# WB32F10x register map
File version: 1.2
CPU: CM3 r2p0, little endian, MPU, no FPU, 4 interrupt priority bits
Registers are 32-bit, read-write, reset 0x0 unless marked. A register's access mark holds for its fields unless they carry their own. Offsets are from the block's base; [hi:lo] are bit positions.

## UART1 — Universal Asynchronous 1
Base 0x40003800
Same registers: UART2 0x40008000, UART3 0x40008400
0x00 RBR ro reset not defined — Receive buffer register
  [8:0] RBR — Receive buffer
0x00 THR wo reset not defined (alternate view of RBR) — Transmit holding register
  [8:0] THR — Transmit hold
0x00 DLL reset not defined (alternate view of RBR) — Divisor latch low register
  [7:0] DLLSB — Divisor latch LSB
0x04 DLH — Divisor latch high register
  [7:0] DLHSB — Divisor latch HSB
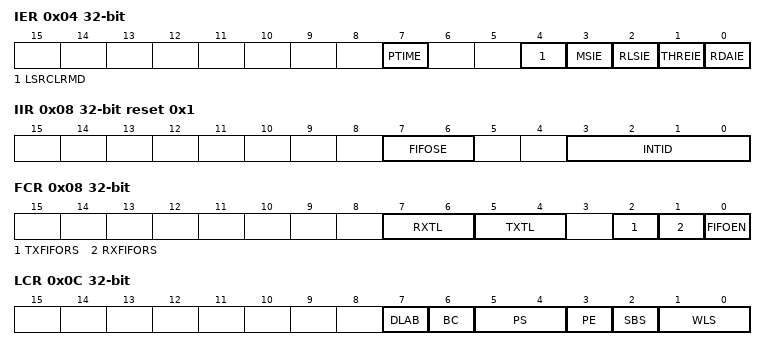
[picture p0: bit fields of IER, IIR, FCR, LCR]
0x04 IER (alternate view of DLH) — Interrupt enable register
  [7] PTIME — Control programmable THRE interrupt.
  [4] LSRCLRMD — This bit is used to control the clearing mode of status bit in LSR register
  [3] MSIE — Modem interrupt control
  [2] RLSIE — Receive interrupt line enable
  [1] THREIE — THRE interrupt enable
  [0] RDAIE — RBR interrupt enable
0x08 IIR ro reset 0x1 — Interrupt identification register
  [7:6] FIFOSE — FIFO enable
  [3:0] INTID — Interrupt identification
0x08 FCR wo (alternate view of IIR) — FIFO control register
  [7:6] RXTL — Receive trigger level
  [5:4] TXTL — Transmit trigger level
  [2] TXFIFORS — Transmit FIFO reset
  [1] RXFIFORS — Receive FIFO reset
  [0] FIFOEN — FIFO enable
0x0C LCR — Line control register
  [7] DLAB — Divisor latch access bit
  [6] BC — Interval control
  [5:4] PS — Parity check selection
  [3] PE — Parity check enable
  [2] SBS — Stop bit selection
  [1:0] WLS — Word length selection
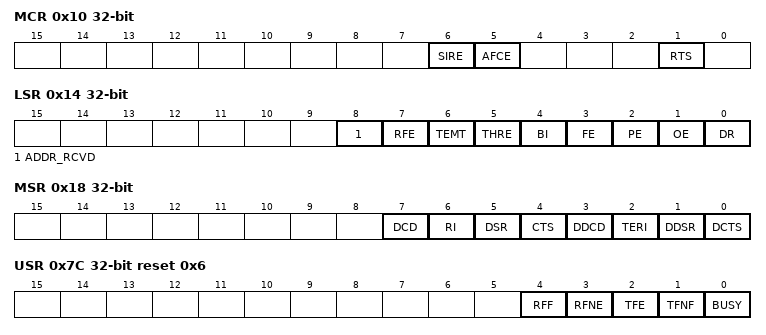
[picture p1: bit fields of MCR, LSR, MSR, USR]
0x10 MCR — Modem control register
  [6] SIRE — IrDA SIR enable
  [5] AFCE — Automatic flow control
  [1] RTS — Modem output pin RTS source
0x14 LSR ro — Line status register
  [8] ADDR_RCVD — Address receive bit
  [7] RFE — Receive FIFO error
  [6] TEMT — Transmitter is empty
  [5] THRE — Transmitter holds the register empty
  [4] BI — Interval interrupt
  [3] FE — Framing error
  [2] PE — Parity check error
  [1] OE — Overflow error
  [0] DR — Data receive ready
0x18 MSR ro — Modem status register
  [7] DCD — Data carrier detection status
  [6] RI — Ringing indicator status
  [5] DSR — Data set ready state
  [4] CTS — Clear transmit status
  [3] DDCD — Delta DCD
  [2] TERI — This bit is set when the input RI is converted from low level to high level
  [1] DDSR — Delta DSR
  [0] DCTS — Delta CTS
0x1C SCR reset not defined — High speed temporary register
  [7:0] PAD — A byte that can be read and written
0x7C USR ro reset 0x6 — Uart status register
  [4] RFF — Receive FIFO is full
  [3] RFNE — Receive FIFO is not empty
  [2] TFE — Transmit FIFO is empty
  [1] TFNF — Transmit FIFO is not full
  [0] BUSY — Busy status
0x80 TFL ro — Transmit FIFO level register
  [3:0] TFL — Data length of transmit FIFO
0x84 RFL ro — Receive FIFO level register
  [3:0] RFL — Data length of Receive FIFO
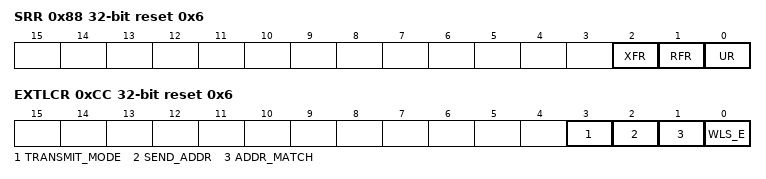
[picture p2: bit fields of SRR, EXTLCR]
0x88 SRR reset 0x6 — Software restart register
  [2] XFR — Shadow bit that sends the FIFO restart control bit FCR [2]
  [1] RFR — Shadow bit of the receive FIFO restart control bit FCR [1]
  [0] UR — UART module restart control bit
0x8C SRTS — Shadow transmit request register
  [0] SRTS — Shadow bit of transmit request control
0x90 SBCR — Shadow interrupt control register
  [0] SBCR — Shadow bit of interrupt control
0x98 SFE — Shadow FIFO enable register
  [0] SFE — Shadow bit of FIFO enable
0x9C SRT — Shadow receive trigger register
  [1:0] SRT — Shadow bit of receive trigger control
0xA0 STET — Shadow Transmit trigger register
  [1:0] STET — Shadow bit of receive Transmit control
0xA8 DMASA — Software abort register
  [0] DMASA — Set this bit to abort DMA transfer
0xC0 DLF — Division latch fraction register
  [3:0] DLF — Division latch fraction
0xC4 RAR ro — Receive address register
  [7:0] RAR — Address of the comparison in receive mode
0xC8 TAR ro — Receive address register
  [7:0] TAR — Address in transmit mode
0xCC EXTLCR reset 0x6 — Extended control register
  [3] TRANSMIT_MODE — Transmission mode
  [2] SEND_ADDR — Send address control bit
  [1] ADDR_MATCH — Address matching enable
  [0] WLS_E — WLS extension
